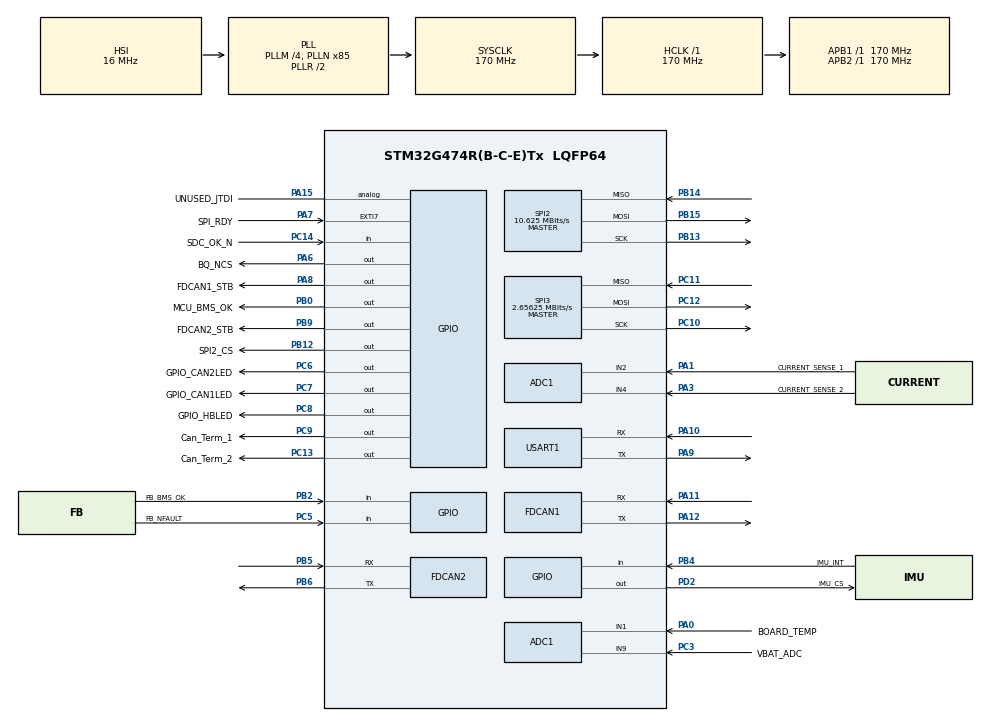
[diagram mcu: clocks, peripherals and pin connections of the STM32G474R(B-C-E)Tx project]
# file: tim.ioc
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ADC1.Channel-0\#ChannelRegularConversion=ADC_CHANNEL_1
ADC1.Channel-1\#ChannelRegularConversion=ADC_CHANNEL_2
ADC1.Channel-2\#ChannelRegularConversion=ADC_CHANNEL_4
ADC1.Channel-3\#ChannelRegularConversion=ADC_CHANNEL_9
ADC1.Channel-4\#ChannelRegularConversion=ADC_CHANNEL_VREFINT
ADC1.ContinuousConvMode=DISABLE
ADC1.DMAContinuousRequests=ENABLE
ADC1.EOCSelection=ADC_EOC_SEQ_CONV
ADC1.ExternalTrigConv=ADC_EXTERNALTRIG_T3_TRGO
ADC1.ExternalTrigConvEdge=ADC_EXTERNALTRIGCONVEDGE_RISING
ADC1.NbrOfConversion=5
ADC1.NbrOfConversionFlag=1
ADC1.OffsetNumber-0\#ChannelRegularConversion=ADC_OFFSET_NONE
ADC1.OffsetNumber-1\#ChannelRegularConversion=ADC_OFFSET_NONE
ADC1.OffsetNumber-2\#ChannelRegularConversion=ADC_OFFSET_NONE
ADC1.OffsetNumber-3\#ChannelRegularConversion=ADC_OFFSET_NONE
ADC1.OffsetNumber-4\#ChannelRegularConversion=ADC_OFFSET_NONE
ADC1.Overrun=ADC_OVR_DATA_OVERWRITTEN
ADC1.Rank-0\#ChannelRegularConversion=1
ADC1.Rank-1\#ChannelRegularConversion=2
ADC1.Rank-2\#ChannelRegularConversion=3
ADC1.Rank-3\#ChannelRegularConversion=4
ADC1.Rank-4\#ChannelRegularConversion=5
ADC1.SamplingTime-0\#ChannelRegularConversion=ADC_SAMPLETIME_640CYCLES_5
ADC1.SamplingTime-1\#ChannelRegularConversion=ADC_SAMPLETIME_640CYCLES_5
ADC1.SamplingTime-2\#ChannelRegularConversion=ADC_SAMPLETIME_640CYCLES_5
ADC1.SamplingTime-3\#ChannelRegularConversion=ADC_SAMPLETIME_640CYCLES_5
ADC1.SamplingTime-4\#ChannelRegularConversion=ADC_SAMPLETIME_640CYCLES_5
ADC1.master=1
Dma.ADC1.2.Direction=DMA_PERIPH_TO_MEMORY
Dma.ADC1.2.EventEnable=DISABLE
Dma.ADC1.2.Instance=DMA1_Channel1
Dma.ADC1.2.MemDataAlignment=DMA_MDATAALIGN_HALFWORD
Dma.ADC1.2.MemInc=DMA_MINC_ENABLE
Dma.ADC1.2.Mode=DMA_CIRCULAR
Dma.ADC1.2.PeriphDataAlignment=DMA_PDATAALIGN_HALFWORD
Dma.ADC1.2.PeriphInc=DMA_PINC_DISABLE
Dma.ADC1.2.Polarity=HAL_DMAMUX_REQ_GEN_RISING
Dma.ADC1.2.Priority=DMA_PRIORITY_HIGH
Dma.ADC1.2.RequestNumber=1
Dma.ADC1.2.SignalID=NONE
Dma.ADC1.2.SyncEnable=DISABLE
Dma.ADC1.2.SyncPolarity=HAL_DMAMUX_SYNC_NO_EVENT
Dma.ADC1.2.SyncRequestNumber=1
Dma.ADC1.2.SyncSignalID=NONE
Dma.Request0=SPI2_RX
Dma.Request1=SPI2_TX
Dma.Request2=ADC1
Dma.Request3=SPI3_RX
Dma.Request4=SPI3_TX
Dma.SPI2_RX.0.Direction=DMA_PERIPH_TO_MEMORY
Dma.SPI2_RX.0.EventEnable=DISABLE
Dma.SPI2_RX.0.Instance=DMA1_Channel3
Dma.SPI2_RX.0.MemDataAlignment=DMA_MDATAALIGN_BYTE
Dma.SPI2_RX.0.MemInc=DMA_MINC_ENABLE
Dma.SPI2_RX.0.Mode=DMA_NORMAL
Dma.SPI2_RX.0.PeriphDataAlignment=DMA_PDATAALIGN_BYTE
Dma.SPI2_RX.0.PeriphInc=DMA_PINC_DISABLE
Dma.SPI2_RX.0.Polarity=HAL_DMAMUX_REQ_GEN_RISING
Dma.SPI2_RX.0.Priority=DMA_PRIORITY_LOW
Dma.SPI2_RX.0.RequestNumber=1
Dma.SPI2_RX.0.SignalID=NONE
Dma.SPI2_RX.0.SyncEnable=DISABLE
Dma.SPI2_RX.0.SyncPolarity=HAL_DMAMUX_SYNC_NO_EVENT
Dma.SPI2_RX.0.SyncRequestNumber=1
Dma.SPI2_RX.0.SyncSignalID=NONE
Dma.SPI2_TX.1.Direction=DMA_MEMORY_TO_PERIPH
Dma.SPI2_TX.1.EventEnable=DISABLE
Dma.SPI2_TX.1.Instance=DMA1_Channel4
Dma.SPI2_TX.1.MemDataAlignment=DMA_MDATAALIGN_BYTE
Dma.SPI2_TX.1.MemInc=DMA_MINC_ENABLE
Dma.SPI2_TX.1.Mode=DMA_NORMAL
Dma.SPI2_TX.1.PeriphDataAlignment=DMA_PDATAALIGN_BYTE
Dma.SPI2_TX.1.PeriphInc=DMA_PINC_DISABLE
Dma.SPI2_TX.1.Polarity=HAL_DMAMUX_REQ_GEN_RISING
Dma.SPI2_TX.1.Priority=DMA_PRIORITY_LOW
Dma.SPI2_TX.1.RequestNumber=1
Dma.SPI2_TX.1.SignalID=NONE
Dma.SPI2_TX.1.SyncEnable=DISABLE
Dma.SPI2_TX.1.SyncPolarity=HAL_DMAMUX_SYNC_NO_EVENT
Dma.SPI2_TX.1.SyncRequestNumber=1
Dma.SPI2_TX.1.SyncSignalID=NONE
Dma.SPI3_RX.3.Direction=DMA_PERIPH_TO_MEMORY
Dma.SPI3_RX.3.EventEnable=DISABLE
Dma.SPI3_RX.3.Instance=DMA1_Channel5
Dma.SPI3_RX.3.MemDataAlignment=DMA_MDATAALIGN_BYTE
Dma.SPI3_RX.3.MemInc=DMA_MINC_ENABLE
Dma.SPI3_RX.3.Mode=DMA_NORMAL
Dma.SPI3_RX.3.PeriphDataAlignment=DMA_PDATAALIGN_BYTE
Dma.SPI3_RX.3.PeriphInc=DMA_PINC_DISABLE
Dma.SPI3_RX.3.Polarity=HAL_DMAMUX_REQ_GEN_RISING
Dma.SPI3_RX.3.Priority=DMA_PRIORITY_HIGH
Dma.SPI3_RX.3.RequestNumber=1
Dma.SPI3_RX.3.SignalID=NONE
Dma.SPI3_RX.3.SyncEnable=DISABLE
Dma.SPI3_RX.3.SyncPolarity=HAL_DMAMUX_SYNC_NO_EVENT
Dma.SPI3_RX.3.SyncRequestNumber=1
Dma.SPI3_RX.3.SyncSignalID=NONE
Dma.SPI3_TX.4.Direction=DMA_MEMORY_TO_PERIPH
Dma.SPI3_TX.4.EventEnable=DISABLE
Dma.SPI3_TX.4.Instance=DMA1_Channel6
Dma.SPI3_TX.4.MemDataAlignment=DMA_MDATAALIGN_BYTE
Dma.SPI3_TX.4.MemInc=DMA_MINC_ENABLE
Dma.SPI3_TX.4.Mode=DMA_NORMAL
Dma.SPI3_TX.4.PeriphDataAlignment=DMA_PDATAALIGN_BYTE
Dma.SPI3_TX.4.PeriphInc=DMA_PINC_DISABLE
Dma.SPI3_TX.4.Polarity=HAL_DMAMUX_REQ_GEN_RISING
Dma.SPI3_TX.4.Priority=DMA_PRIORITY_HIGH
Dma.SPI3_TX.4.RequestNumber=1
Dma.SPI3_TX.4.SignalID=NONE
Dma.SPI3_TX.4.SyncEnable=DISABLE
Dma.SPI3_TX.4.SyncPolarity=HAL_DMAMUX_SYNC_NO_EVENT
Dma.SPI3_TX.4.SyncRequestNumber=1
Dma.SPI3_TX.4.SyncSignalID=NONE
FDCAN1.AutoRetransmission=ENABLE
FDCAN1.CalculateBaudRateNominal=500000
FDCAN1.CalculateTimeBitNominal=2000
FDCAN1.CalculateTimeQuantumNominal=100.0
FDCAN1.ExtFiltersNbr=1
FDCAN1.FrameFormat=FDCAN_FRAME_CLASSIC
FDCAN1.NominalPrescaler=17
FDCAN1.NominalSyncJumpWidth=4
FDCAN1.NominalTimeSeg1=15
FDCAN1.NominalTimeSeg2=4
FDCAN1.TxFifoQueueMode=FDCAN_TX_QUEUE_OPERATION
FDCAN2.AutoRetransmission=ENABLE
FDCAN2.CalculateBaudRateNominal=500000
FDCAN2.CalculateTimeBitNominal=2000
FDCAN2.CalculateTimeQuantumNominal=100.0
FDCAN2.DataPrescaler=5
FDCAN2.DataSyncJumpWidth=3
FDCAN2.DataTimeSeg1=13
FDCAN2.DataTimeSeg2=3
FDCAN2.FrameFormat=FDCAN_FRAME_FD_BRS
FDCAN2.NominalPrescaler=17
FDCAN2.NominalSyncJumpWidth=4
FDCAN2.NominalTimeSeg1=15
FDCAN2.NominalTimeSeg2=4
FREERTOS.Tasks01=initTask,24,128,StartDefaultTask,Default,NULL,Dynamic,NULL,NULL
FREERTOS.configTOTAL_HEAP_SIZE=32768
FREERTOS.configUSE_NEWLIB_REENTRANT=1
Mcu.Family=STM32G4
Mcu.Name=STM32G474R(B-C-E)Tx
Mcu.Package=LQFP64
NVIC.DMA1_Channel1_IRQn=true\:9\:0\:true\:false\:true\:true\:true\:true\:true
NVIC.DMA1_Channel3_IRQn=true\:9\:0\:true\:false\:true\:true\:true\:true\:true
NVIC.DMA1_Channel4_IRQn=true\:9\:0\:true\:false\:true\:true\:true\:true\:true
NVIC.DMA1_Channel5_IRQn=true\:6\:0\:true\:false\:true\:true\:true\:true\:true
NVIC.DMA1_Channel6_IRQn=true\:6\:0\:true\:false\:true\:true\:true\:true\:true
NVIC.EXTI9_5_IRQn=true\:6\:0\:true\:false\:true\:true\:true\:true\:true
NVIC.FDCAN1_IT0_IRQn=true\:5\:0\:false\:false\:true\:true\:true\:true\:true
NVIC.FDCAN1_IT1_IRQn=true\:5\:0\:false\:false\:true\:true\:true\:true\:true
NVIC.FDCAN2_IT0_IRQn=true\:7\:0\:true\:false\:true\:true\:true\:true\:true
NVIC.FDCAN2_IT1_IRQn=true\:7\:0\:true\:false\:true\:true\:true\:true\:true
NVIC.PriorityGroup=NVIC_PRIORITYGROUP_4
NVIC.SPI2_IRQn=true\:9\:0\:true\:false\:true\:true\:true\:true\:true
NVIC.SPI3_IRQn=true\:6\:0\:true\:false\:true\:true\:true\:true\:true
NVIC.TIM6_DAC_IRQn=true\:15\:0\:false\:false\:true\:false\:false\:true\:true
NVIC.TimeBase=TIM6_DAC_IRQn
NVIC.TimeBaseIP=TIM6
NVIC.USART1_IRQn=true\:9\:0\:true\:false\:true\:true\:true\:true\:true
PA0.GPIO_Label=BOARD_TEMP
PA0.Mode=IN1-Single-Ended
PA0.Signal=ADC1_IN1
PA1.GPIO_Label=CURRENT_SENSE_1
PA1.Mode=IN2-Single-Ended
PA1.Signal=ADC1_IN2
PA10.Mode=Asynchronous
PA10.Signal=USART1_RX
PA11.Mode=FDCAN_Activate
PA11.Signal=FDCAN1_RX
PA12.Mode=FDCAN_Activate
PA12.Signal=FDCAN1_TX
PA13.GPIO_Label=SWDIO
PA13.Mode=Trace_Asynchronous_SW
PA13.Signal=SYS_JTMS-SWDIO
PA14.GPIO_Label=SWCLK
PA14.Mode=Trace_Asynchronous_SW
PA14.Signal=SYS_JTCK-SWCLK
PA15.GPIO_Label=UNUSED_JTDI
PA15.Signal=GPIO_Analog
PA3.GPIO_Label=CURRENT_SENSE_2
PA3.Mode=IN4-Single-Ended
PA3.Signal=ADC1_IN4
PA6.GPIO_Label=BQ_NCS
PA6.PinState=GPIO_PIN_SET
PA6.Signal=GPIO_Output
PA7.GPIO_Label=SPI_RDY
PA7.GPIO_ModeDefaultEXTI=GPIO_MODE_IT_RISING
PA7.GPIO_PuPd=GPIO_PULLUP
PA7.Signal=GPXTI7
PA8.GPIO_Label=FDCAN1_STB
PA8.PinState=GPIO_PIN_SET
PA8.Signal=GPIO_Output
PA9.Mode=Asynchronous
PA9.Signal=USART1_TX
PB0.GPIO_Label=MCU_BMS_OK
PB0.GPIO_PuPd=GPIO_NOPULL
PB0.PinState=GPIO_PIN_RESET
PB0.Signal=GPIO_Output
PB12.GPIO_Label=SPI2_CS
PB12.PinState=GPIO_PIN_SET
PB12.Signal=GPIO_Output
PB13.GPIO_Speed=GPIO_SPEED_FREQ_MEDIUM
PB13.Mode=Full_Duplex_Master
PB13.Signal=SPI2_SCK
PB14.Mode=Full_Duplex_Master
PB14.Signal=SPI2_MISO
PB15.GPIO_Speed=GPIO_SPEED_FREQ_MEDIUM
PB15.Mode=Full_Duplex_Master
PB15.Signal=SPI2_MOSI
PB2.GPIO_Label=FB_BMS_OK
PB2.Signal=GPIO_Input
PB3.GPIO_Label=SWO
PB3.Mode=Trace_Asynchronous_SW
PB3.Signal=SYS_JTDO-SWO
PB4.GPIO_Label=IMU_INT
PB4.GPIO_PuPd=GPIO_PULLDOWN
PB4.Signal=GPIO_Input
PB5.Mode=FDCAN_Activate
PB5.Signal=FDCAN2_RX
PB6.Mode=FDCAN_Activate
PB6.Signal=FDCAN2_TX
PB9.GPIO_Label=FDCAN2_STB
PB9.PinState=GPIO_PIN_SET
PB9.Signal=GPIO_Output
PC10.Mode=Full_Duplex_Master
PC10.Signal=SPI3_SCK
PC11.Mode=Full_Duplex_Master
PC11.Signal=SPI3_MISO
PC12.Mode=Full_Duplex_Master
PC12.Signal=SPI3_MOSI
PC13.GPIO_Label=Can_Term_2
PC13.Signal=GPIO_Output
PC14-OSC32_IN.GPIO_Label=SDC_OK_N
PC14-OSC32_IN.Signal=GPIO_Input
PC3.GPIO_Label=VBAT_ADC
PC3.Mode=IN9-Single-Ended
PC3.Signal=ADC1_IN9
PC5.GPIO_Label=FB_NFAULT
PC5.Signal=GPIO_Input
PC6.GPIO_Label=GPIO_CAN2LED
PC6.GPIO_ModeDefaultOutputPP=GPIO_MODE_OUTPUT_PP
PC6.GPIO_PuPd=GPIO_NOPULL
PC6.PinState=GPIO_PIN_SET
PC6.Signal=GPIO_Output
PC7.GPIO_Label=GPIO_CAN1LED
PC7.GPIO_ModeDefaultOutputPP=GPIO_MODE_OUTPUT_PP
PC7.GPIO_PuPd=GPIO_NOPULL
PC7.PinState=GPIO_PIN_SET
PC7.Signal=GPIO_Output
PC8.GPIO_Label=GPIO_HBLED
PC8.GPIO_ModeDefaultOutputPP=GPIO_MODE_OUTPUT_PP
PC8.GPIO_PuPd=GPIO_NOPULL
PC8.PinState=GPIO_PIN_SET
PC8.Signal=GPIO_Output
PC9.GPIO_Label=Can_Term_1
PC9.Signal=GPIO_Output
PD2.GPIO_Label=IMU_CS
PD2.PinState=GPIO_PIN_SET
PD2.Signal=GPIO_Output
PF0-OSC_IN.Mode=HSE-External-Oscillator
PF0-OSC_IN.Signal=RCC_OSC_IN
PF1-OSC_OUT.Mode=HSE-External-Oscillator
PF1-OSC_OUT.Signal=RCC_OSC_OUT
ProjectManager.HeapSize=0x200
ProjectManager.StackSize=0x400
ProjectManager.TargetToolchain=CMake
RCC.ADC12Freq_Value=170000000
RCC.ADC345Freq_Value=170000000
RCC.AHBFreq_Value=170000000
RCC.APB1Freq_Value=170000000
RCC.APB1TimFreq_Value=170000000
RCC.APB2Freq_Value=170000000
RCC.APB2TimFreq_Value=170000000
RCC.CortexFreq_Value=170000000
RCC.EXTERNAL_CLOCK_VALUE=12288000
RCC.HCLKFreq_Value=170000000
RCC.HSE_VALUE=8000000
RCC.HSI48_VALUE=48000000
RCC.HSI_VALUE=16000000
RCC.LSE_VALUE=32768
RCC.PLLM=RCC_PLLM_DIV4
RCC.PLLN=85
RCC.SYSCLKFreq_VALUE=170000000
RCC.SYSCLKSource=RCC_SYSCLKSOURCE_PLLCLK
RCC.USBFreq_Value=170000000
RCC.VCOOutputFreq_Value=340000000
SPI2.BaudRatePrescaler=SPI_BAUDRATEPRESCALER_16
SPI2.CalculateBaudRate=10.625 MBits/s
SPI2.DataSize=SPI_DATASIZE_8BIT
SPI2.Direction=SPI_DIRECTION_2LINES
SPI2.Mode=SPI_MODE_MASTER
SPI2.VirtualType=VM_MASTER
SPI3.BaudRatePrescaler=SPI_BAUDRATEPRESCALER_64
SPI3.CalculateBaudRate=2.65625 MBits/s
SPI3.DataSize=SPI_DATASIZE_8BIT
SPI3.Direction=SPI_DIRECTION_2LINES
SPI3.Mode=SPI_MODE_MASTER
SPI3.VirtualType=VM_MASTER
TIM3.Period=999
TIM3.Prescaler=169
TIM3.TIM_MasterOutputTrigger=TIM_TRGO_UPDATE
USART1.VirtualMode-Asynchronous=VM_ASYNC
VP_ADC1_Vref_Input.Mode=IN-Vrefint
VP_FATFS_VS_Generic.Mode=User_defined
VP_FREERTOS_VS_CMSIS_V2.Mode=CMSIS_V2
VP_SYS_VS_DBSignals.Mode=DisableDeadBatterySignals
VP_SYS_VS_tim6.Mode=TIM6
VP_TIM3_VS_ClockSourceINT.Mode=Internal
board=custom

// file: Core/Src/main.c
/* USER CODE BEGIN Header */
/**
  ******************************************************************************
  * @file           : main.c
  * @brief          : Main program body
  ******************************************************************************
  * @attention
  *
  * Copyright (c) 2026 STMicroelectronics.
  * All rights reserved.
  *
  * This software is licensed under terms that can be found in the LICENSE file
  * in the root directory of this software component.
  * If no LICENSE file comes with this software, it is provided AS-IS.
  *
  ******************************************************************************
  */
/* USER CODE END Header */
#include "main.h"
#include "cmsis_os.h"
#include "app_fatfs.h"

/* USER CODE BEGIN Includes */
#include "tasks.h"
#include "watchdog.h"
#include "crash.h"
#include "reset_info.h"
/* USER CODE END Includes */

ADC_HandleTypeDef hadc1;
DMA_HandleTypeDef hdma_adc1;

FDCAN_HandleTypeDef hfdcan1;
FDCAN_HandleTypeDef hfdcan2;

SPI_HandleTypeDef hspi2;
SPI_HandleTypeDef hspi3;
DMA_HandleTypeDef hdma_spi2_rx;
DMA_HandleTypeDef hdma_spi2_tx;
DMA_HandleTypeDef hdma_spi3_rx;
DMA_HandleTypeDef hdma_spi3_tx;

TIM_HandleTypeDef htim3;

UART_HandleTypeDef huart1;

/* Definitions for initTask */
osThreadId_t initTaskHandle;
const osThreadAttr_t initTask_attributes = {
  .name = "initTask",
  .priority = (osPriority_t) osPriorityNormal,
  .stack_size = 128 * 4
};

void SystemClock_Config(void);
static void MX_GPIO_Init(void);
static void MX_DMA_Init(void);
static void MX_ADC1_Init(void);
static void MX_FDCAN1_Init(void);
static void MX_FDCAN2_Init(void);
static void MX_SPI2_Init(void);
static void MX_SPI3_Init(void);
static void MX_TIM3_Init(void);
static void MX_USART1_UART_Init(void);
void StartDefaultTask(void *argument);

int main(void)
{

  /* USER CODE BEGIN 1 */
  /* Before anything else: read, keep and clear the reset cause, and keep
     the Breadcrumb and Crash record found (reset_info.h, ADR 0011). */
  reset_info_capture();
  /* USER CODE END 1 */

  /* MCU Configuration--------------------------------------------------------*/

  /* Reset of all peripherals, Initializes the Flash interface and the Systick. */
  HAL_Init();

  /* Configure the system clock */
  SystemClock_Config();

  /* Initialize all configured peripherals */
  MX_GPIO_Init();
  MX_DMA_Init();
  MX_ADC1_Init();
  MX_FDCAN1_Init();
  MX_FDCAN2_Init();
  MX_SPI2_Init();
  MX_SPI3_Init();
  MX_TIM3_Init();
  MX_USART1_UART_Init();
  if (MX_FATFS_Init() != APP_OK) {
    Error_Handler();
  }
  /* USER CODE BEGIN 2 */
  /* Start-up Kick 1 of 2, after the peripheral init (watchdog.h). */
  watchdog_kick();
  /* USER CODE END 2 */

  /* Init scheduler */
  osKernelInitialize();

  /* Create the thread(s) */
  /* creation of initTask */
  initTaskHandle = osThreadNew(StartDefaultTask, NULL, &initTask_attributes);

  /* Start scheduler */
  osKernelStart();

  /* We should never get here as control is now taken by the scheduler */

  /* Infinite loop */
  while (1)
  {

  }
}

void SystemClock_Config(void)
{
  RCC_OscInitTypeDef RCC_OscInitStruct = {0};
  RCC_ClkInitTypeDef RCC_ClkInitStruct = {0};

  /** Configure the main internal regulator output voltage
  */
  HAL_PWREx_ControlVoltageScaling(PWR_REGULATOR_VOLTAGE_SCALE1_BOOST);

  /** Initializes the RCC Oscillators according to the specified parameters
  * in the RCC_OscInitTypeDef structure.
  */
  RCC_OscInitStruct.OscillatorType = RCC_OSCILLATORTYPE_HSI;
  RCC_OscInitStruct.HSIState = RCC_HSI_ON;
  RCC_OscInitStruct.HSICalibrationValue = RCC_HSICALIBRATION_DEFAULT;
  RCC_OscInitStruct.PLL.PLLState = RCC_PLL_ON;
  RCC_OscInitStruct.PLL.PLLSource = RCC_PLLSOURCE_HSI;
  RCC_OscInitStruct.PLL.PLLM = RCC_PLLM_DIV4;
  RCC_OscInitStruct.PLL.PLLN = 85;
  RCC_OscInitStruct.PLL.PLLP = RCC_PLLP_DIV2;
  RCC_OscInitStruct.PLL.PLLQ = RCC_PLLQ_DIV2;
  RCC_OscInitStruct.PLL.PLLR = RCC_PLLR_DIV2;
  if (HAL_RCC_OscConfig(&RCC_OscInitStruct) != HAL_OK)
  {
    Error_Handler();
  }

  /** Initializes the CPU, AHB and APB buses clocks
  */
  RCC_ClkInitStruct.ClockType = RCC_CLOCKTYPE_HCLK|RCC_CLOCKTYPE_SYSCLK
                              |RCC_CLOCKTYPE_PCLK1|RCC_CLOCKTYPE_PCLK2;
  RCC_ClkInitStruct.SYSCLKSource = RCC_SYSCLKSOURCE_PLLCLK;
  RCC_ClkInitStruct.AHBCLKDivider = RCC_SYSCLK_DIV1;
  RCC_ClkInitStruct.APB1CLKDivider = RCC_HCLK_DIV1;
  RCC_ClkInitStruct.APB2CLKDivider = RCC_HCLK_DIV1;

  if (HAL_RCC_ClockConfig(&RCC_ClkInitStruct, FLASH_LATENCY_4) != HAL_OK)
  {
    Error_Handler();
  }
}

static void MX_ADC1_Init(void)
{

  ADC_MultiModeTypeDef multimode = {0};
  ADC_ChannelConfTypeDef sConfig = {0};

  /** Common config
  */
  hadc1.Instance = ADC1;
  hadc1.Init.ClockPrescaler = ADC_CLOCK_SYNC_PCLK_DIV4;
  hadc1.Init.Resolution = ADC_RESOLUTION_12B;
  hadc1.Init.DataAlign = ADC_DATAALIGN_RIGHT;
  hadc1.Init.GainCompensation = 0;
  hadc1.Init.ScanConvMode = ADC_SCAN_ENABLE;
  hadc1.Init.EOCSelection = ADC_EOC_SEQ_CONV;
  hadc1.Init.LowPowerAutoWait = DISABLE;
  hadc1.Init.ContinuousConvMode = DISABLE;
  hadc1.Init.NbrOfConversion = 5;
  hadc1.Init.DiscontinuousConvMode = DISABLE;
  hadc1.Init.ExternalTrigConv = ADC_EXTERNALTRIG_T3_TRGO;
  hadc1.Init.ExternalTrigConvEdge = ADC_EXTERNALTRIGCONVEDGE_RISING;
  hadc1.Init.DMAContinuousRequests = ENABLE;
  hadc1.Init.Overrun = ADC_OVR_DATA_OVERWRITTEN;
  hadc1.Init.OversamplingMode = DISABLE;
  if (HAL_ADC_Init(&hadc1) != HAL_OK)
  {
    Error_Handler();
  }

  /** Configure the ADC multi-mode
  */
  multimode.Mode = ADC_MODE_INDEPENDENT;
  if (HAL_ADCEx_MultiModeConfigChannel(&hadc1, &multimode) != HAL_OK)
  {
    Error_Handler();
  }

  /** Configure Regular Channel
  */
  sConfig.Channel = ADC_CHANNEL_1;
  sConfig.Rank = ADC_REGULAR_RANK_1;
  sConfig.SamplingTime = ADC_SAMPLETIME_640CYCLES_5;
  sConfig.SingleDiff = ADC_SINGLE_ENDED;
  sConfig.OffsetNumber = ADC_OFFSET_NONE;
  sConfig.Offset = 0;
  if (HAL_ADC_ConfigChannel(&hadc1, &sConfig) != HAL_OK)
  {
    Error_Handler();
  }

  /** Configure Regular Channel
  */
  sConfig.Channel = ADC_CHANNEL_2;
  sConfig.Rank = ADC_REGULAR_RANK_2;
  if (HAL_ADC_ConfigChannel(&hadc1, &sConfig) != HAL_OK)
  {
    Error_Handler();
  }

  /** Configure Regular Channel
  */
  sConfig.Channel = ADC_CHANNEL_4;
  sConfig.Rank = ADC_REGULAR_RANK_3;
  if (HAL_ADC_ConfigChannel(&hadc1, &sConfig) != HAL_OK)
  {
    Error_Handler();
  }

  /** Configure Regular Channel
  */
  sConfig.Channel = ADC_CHANNEL_9;
  sConfig.Rank = ADC_REGULAR_RANK_4;
  if (HAL_ADC_ConfigChannel(&hadc1, &sConfig) != HAL_OK)
  {
    Error_Handler();
  }

  /** Configure Regular Channel
  */
  sConfig.Channel = ADC_CHANNEL_VREFINT;
  sConfig.Rank = ADC_REGULAR_RANK_5;
  if (HAL_ADC_ConfigChannel(&hadc1, &sConfig) != HAL_OK)
  {
    Error_Handler();
  }

}

static void MX_FDCAN1_Init(void)
{

  hfdcan1.Instance = FDCAN1;
  hfdcan1.Init.ClockDivider = FDCAN_CLOCK_DIV1;
  hfdcan1.Init.FrameFormat = FDCAN_FRAME_CLASSIC;
  hfdcan1.Init.Mode = FDCAN_MODE_NORMAL;
  hfdcan1.Init.AutoRetransmission = ENABLE;
  hfdcan1.Init.TransmitPause = DISABLE;
  hfdcan1.Init.ProtocolException = DISABLE;
  hfdcan1.Init.NominalPrescaler = 17;
  hfdcan1.Init.NominalSyncJumpWidth = 4;
  hfdcan1.Init.NominalTimeSeg1 = 15;
  hfdcan1.Init.NominalTimeSeg2 = 4;
  hfdcan1.Init.DataPrescaler = 1;
  hfdcan1.Init.DataSyncJumpWidth = 1;
  hfdcan1.Init.DataTimeSeg1 = 1;
  hfdcan1.Init.DataTimeSeg2 = 1;
  hfdcan1.Init.StdFiltersNbr = 0;
  hfdcan1.Init.ExtFiltersNbr = 1;
  hfdcan1.Init.TxFifoQueueMode = FDCAN_TX_QUEUE_OPERATION;
  if (HAL_FDCAN_Init(&hfdcan1) != HAL_OK)
  {
    Error_Handler();
  }

}

static void MX_FDCAN2_Init(void)
{

  hfdcan2.Instance = FDCAN2;
  hfdcan2.Init.ClockDivider = FDCAN_CLOCK_DIV1;
  hfdcan2.Init.FrameFormat = FDCAN_FRAME_FD_BRS;
  hfdcan2.Init.Mode = FDCAN_MODE_NORMAL;
  hfdcan2.Init.AutoRetransmission = ENABLE;
  hfdcan2.Init.TransmitPause = DISABLE;
  hfdcan2.Init.ProtocolException = DISABLE;
  hfdcan2.Init.NominalPrescaler = 17;
  hfdcan2.Init.NominalSyncJumpWidth = 4;
  hfdcan2.Init.NominalTimeSeg1 = 15;
  hfdcan2.Init.NominalTimeSeg2 = 4;
  hfdcan2.Init.DataPrescaler = 5;
  hfdcan2.Init.DataSyncJumpWidth = 3;
  hfdcan2.Init.DataTimeSeg1 = 13;
  hfdcan2.Init.DataTimeSeg2 = 3;
  hfdcan2.Init.StdFiltersNbr = 0;
  hfdcan2.Init.ExtFiltersNbr = 0;
  hfdcan2.Init.TxFifoQueueMode = FDCAN_TX_FIFO_OPERATION;
  if (HAL_FDCAN_Init(&hfdcan2) != HAL_OK)
  {
    Error_Handler();
  }

}

static void MX_SPI2_Init(void)
{

  /* SPI2 parameter configuration*/
  hspi2.Instance = SPI2;
  hspi2.Init.Mode = SPI_MODE_MASTER;
  hspi2.Init.Direction = SPI_DIRECTION_2LINES;
  hspi2.Init.DataSize = SPI_DATASIZE_8BIT;
  hspi2.Init.CLKPolarity = SPI_POLARITY_LOW;
  hspi2.Init.CLKPhase = SPI_PHASE_1EDGE;
  hspi2.Init.NSS = SPI_NSS_SOFT;
  hspi2.Init.BaudRatePrescaler = SPI_BAUDRATEPRESCALER_16;
  hspi2.Init.FirstBit = SPI_FIRSTBIT_MSB;
  hspi2.Init.TIMode = SPI_TIMODE_DISABLE;
  hspi2.Init.CRCCalculation = SPI_CRCCALCULATION_DISABLE;
  hspi2.Init.CRCPolynomial = 7;
  hspi2.Init.CRCLength = SPI_CRC_LENGTH_DATASIZE;
  hspi2.Init.NSSPMode = SPI_NSS_PULSE_ENABLE;
  if (HAL_SPI_Init(&hspi2) != HAL_OK)
  {
    Error_Handler();
  }

}

static void MX_SPI3_Init(void)
{

  /* SPI3 parameter configuration*/
  hspi3.Instance = SPI3;
  hspi3.Init.Mode = SPI_MODE_MASTER;
  hspi3.Init.Direction = SPI_DIRECTION_2LINES;
  hspi3.Init.DataSize = SPI_DATASIZE_8BIT;
  hspi3.Init.CLKPolarity = SPI_POLARITY_LOW;
  hspi3.Init.CLKPhase = SPI_PHASE_1EDGE;
  hspi3.Init.NSS = SPI_NSS_SOFT;
  hspi3.Init.BaudRatePrescaler = SPI_BAUDRATEPRESCALER_64;
  hspi3.Init.FirstBit = SPI_FIRSTBIT_MSB;
  hspi3.Init.TIMode = SPI_TIMODE_DISABLE;
  hspi3.Init.CRCCalculation = SPI_CRCCALCULATION_DISABLE;
  hspi3.Init.CRCPolynomial = 7;
  hspi3.Init.CRCLength = SPI_CRC_LENGTH_DATASIZE;
  hspi3.Init.NSSPMode = SPI_NSS_PULSE_ENABLE;
  if (HAL_SPI_Init(&hspi3) != HAL_OK)
  {
    Error_Handler();
  }

}

static void MX_TIM3_Init(void)
{

  TIM_ClockConfigTypeDef sClockSourceConfig = {0};
  TIM_MasterConfigTypeDef sMasterConfig = {0};

  htim3.Instance = TIM3;
  htim3.Init.Prescaler = 169;
  htim3.Init.CounterMode = TIM_COUNTERMODE_UP;
  htim3.Init.Period = 999;
  htim3.Init.ClockDivision = TIM_CLOCKDIVISION_DIV1;
  htim3.Init.AutoReloadPreload = TIM_AUTORELOAD_PRELOAD_DISABLE;
  if (HAL_TIM_Base_Init(&htim3) != HAL_OK)
  {
    Error_Handler();
  }
  sClockSourceConfig.ClockSource = TIM_CLOCKSOURCE_INTERNAL;
  if (HAL_TIM_ConfigClockSource(&htim3, &sClockSourceConfig) != HAL_OK)
  {
    Error_Handler();
  }
  sMasterConfig.MasterOutputTrigger = TIM_TRGO_UPDATE;
  sMasterConfig.MasterSlaveMode = TIM_MASTERSLAVEMODE_DISABLE;
  if (HAL_TIMEx_MasterConfigSynchronization(&htim3, &sMasterConfig) != HAL_OK)
  {
    Error_Handler();
  }

}

static void MX_USART1_UART_Init(void)
{

  huart1.Instance = USART1;
  huart1.Init.BaudRate = 115200;
  huart1.Init.WordLength = UART_WORDLENGTH_8B;
  huart1.Init.StopBits = UART_STOPBITS_1;
  huart1.Init.Parity = UART_PARITY_NONE;
  huart1.Init.Mode = UART_MODE_TX_RX;
  huart1.Init.HwFlowCtl = UART_HWCONTROL_NONE;
  huart1.Init.OverSampling = UART_OVERSAMPLING_16;
  huart1.Init.OneBitSampling = UART_ONE_BIT_SAMPLE_DISABLE;
  huart1.Init.ClockPrescaler = UART_PRESCALER_DIV1;
  huart1.AdvancedInit.AdvFeatureInit = UART_ADVFEATURE_NO_INIT;
  if (HAL_UART_Init(&huart1) != HAL_OK)
  {
    Error_Handler();
  }
  if (HAL_UARTEx_SetTxFifoThreshold(&huart1, UART_TXFIFO_THRESHOLD_1_8) != HAL_OK)
  {
    Error_Handler();
  }
  if (HAL_UARTEx_SetRxFifoThreshold(&huart1, UART_RXFIFO_THRESHOLD_1_8) != HAL_OK)
  {
    Error_Handler();
  }
  if (HAL_UARTEx_DisableFifoMode(&huart1) != HAL_OK)
  {
    Error_Handler();
  }

}

static void MX_DMA_Init(void)
{

  /* DMA controller clock enable */
  __HAL_RCC_DMAMUX1_CLK_ENABLE();
  __HAL_RCC_DMA1_CLK_ENABLE();

  /* DMA interrupt init */
  /* DMA1_Channel1_IRQn interrupt configuration */
  HAL_NVIC_SetPriority(DMA1_Channel1_IRQn, 9, 0);
  HAL_NVIC_EnableIRQ(DMA1_Channel1_IRQn);
  /* DMA1_Channel3_IRQn interrupt configuration */
  HAL_NVIC_SetPriority(DMA1_Channel3_IRQn, 9, 0);
  HAL_NVIC_EnableIRQ(DMA1_Channel3_IRQn);
  /* DMA1_Channel4_IRQn interrupt configuration */
  HAL_NVIC_SetPriority(DMA1_Channel4_IRQn, 9, 0);
  HAL_NVIC_EnableIRQ(DMA1_Channel4_IRQn);
  /* DMA1_Channel5_IRQn interrupt configuration */
  HAL_NVIC_SetPriority(DMA1_Channel5_IRQn, 6, 0);
  HAL_NVIC_EnableIRQ(DMA1_Channel5_IRQn);
  /* DMA1_Channel6_IRQn interrupt configuration */
  HAL_NVIC_SetPriority(DMA1_Channel6_IRQn, 6, 0);
  HAL_NVIC_EnableIRQ(DMA1_Channel6_IRQn);

}

static void MX_GPIO_Init(void)
{
  GPIO_InitTypeDef GPIO_InitStruct = {0};

  /* GPIO Ports Clock Enable */
  __HAL_RCC_GPIOC_CLK_ENABLE();
  __HAL_RCC_GPIOF_CLK_ENABLE();
  __HAL_RCC_GPIOA_CLK_ENABLE();
  __HAL_RCC_GPIOB_CLK_ENABLE();
  __HAL_RCC_GPIOD_CLK_ENABLE();

  /*Configure GPIO pin Output Level */
  HAL_GPIO_WritePin(GPIOC, Can_Term_2_Pin|Can_Term_1_Pin, GPIO_PIN_RESET);

  /*Configure GPIO pin Output Level */
  HAL_GPIO_WritePin(GPIOA, BQ_NCS_Pin|FDCAN1_STB_Pin, GPIO_PIN_SET);

  /*Configure GPIO pin Output Level */
  HAL_GPIO_WritePin(MCU_BMS_OK_GPIO_Port, MCU_BMS_OK_Pin, GPIO_PIN_RESET);

  /*Configure GPIO pin Output Level */
  HAL_GPIO_WritePin(GPIOB, SPI2_CS_Pin|FDCAN2_STB_Pin, GPIO_PIN_SET);

  /*Configure GPIO pin Output Level */
  HAL_GPIO_WritePin(GPIOC, GPIO_CAN2LED_Pin|GPIO_CAN1LED_Pin|GPIO_HBLED_Pin, GPIO_PIN_SET);

  /*Configure GPIO pin Output Level */
  HAL_GPIO_WritePin(IMU_CS_GPIO_Port, IMU_CS_Pin, GPIO_PIN_SET);

  /*Configure GPIO pins : Can_Term_2_Pin GPIO_CAN2LED_Pin GPIO_CAN1LED_Pin GPIO_HBLED_Pin
                           Can_Term_1_Pin */
  GPIO_InitStruct.Pin = Can_Term_2_Pin|GPIO_CAN2LED_Pin|GPIO_CAN1LED_Pin|GPIO_HBLED_Pin
                          |Can_Term_1_Pin;
  GPIO_InitStruct.Mode = GPIO_MODE_OUTPUT_PP;
  GPIO_InitStruct.Pull = GPIO_NOPULL;
  GPIO_InitStruct.Speed = GPIO_SPEED_FREQ_LOW;
  HAL_GPIO_Init(GPIOC, &GPIO_InitStruct);

  /*Configure GPIO pins : SDC_OK_N_Pin FB_NFAULT_Pin */
  GPIO_InitStruct.Pin = SDC_OK_N_Pin|FB_NFAULT_Pin;
  GPIO_InitStruct.Mode = GPIO_MODE_INPUT;
  GPIO_InitStruct.Pull = GPIO_NOPULL;
  HAL_GPIO_Init(GPIOC, &GPIO_InitStruct);

  /*Configure GPIO pins : BQ_NCS_Pin FDCAN1_STB_Pin */
  GPIO_InitStruct.Pin = BQ_NCS_Pin|FDCAN1_STB_Pin;
  GPIO_InitStruct.Mode = GPIO_MODE_OUTPUT_PP;
  GPIO_InitStruct.Pull = GPIO_NOPULL;
  GPIO_InitStruct.Speed = GPIO_SPEED_FREQ_LOW;
  HAL_GPIO_Init(GPIOA, &GPIO_InitStruct);

  /*Configure GPIO pin : SPI_RDY_Pin */
  GPIO_InitStruct.Pin = SPI_RDY_Pin;
  GPIO_InitStruct.Mode = GPIO_MODE_IT_RISING;
  GPIO_InitStruct.Pull = GPIO_PULLUP;
  HAL_GPIO_Init(SPI_RDY_GPIO_Port, &GPIO_InitStruct);

  /*Configure GPIO pins : MCU_BMS_OK_Pin SPI2_CS_Pin FDCAN2_STB_Pin */
  GPIO_InitStruct.Pin = MCU_BMS_OK_Pin|SPI2_CS_Pin|FDCAN2_STB_Pin;
  GPIO_InitStruct.Mode = GPIO_MODE_OUTPUT_PP;
  GPIO_InitStruct.Pull = GPIO_NOPULL;
  GPIO_InitStruct.Speed = GPIO_SPEED_FREQ_LOW;
  HAL_GPIO_Init(GPIOB, &GPIO_InitStruct);

  /*Configure GPIO pin : FB_BMS_OK_Pin */
  GPIO_InitStruct.Pin = FB_BMS_OK_Pin;
  GPIO_InitStruct.Mode = GPIO_MODE_INPUT;
  GPIO_InitStruct.Pull = GPIO_NOPULL;
  HAL_GPIO_Init(FB_BMS_OK_GPIO_Port, &GPIO_InitStruct);

  /*Configure GPIO pin : UNUSED_JTDI_Pin */
  GPIO_InitStruct.Pin = UNUSED_JTDI_Pin;
  GPIO_InitStruct.Mode = GPIO_MODE_ANALOG;
  GPIO_InitStruct.Pull = GPIO_NOPULL;
  HAL_GPIO_Init(UNUSED_JTDI_GPIO_Port, &GPIO_InitStruct);

  /*Configure GPIO pin : IMU_CS_Pin */
  GPIO_InitStruct.Pin = IMU_CS_Pin;
  GPIO_InitStruct.Mode = GPIO_MODE_OUTPUT_PP;
  GPIO_InitStruct.Pull = GPIO_NOPULL;
  GPIO_InitStruct.Speed = GPIO_SPEED_FREQ_LOW;
  HAL_GPIO_Init(IMU_CS_GPIO_Port, &GPIO_InitStruct);

  /*Configure GPIO pin : IMU_INT_Pin */
  GPIO_InitStruct.Pin = IMU_INT_Pin;
  GPIO_InitStruct.Mode = GPIO_MODE_INPUT;
  GPIO_InitStruct.Pull = GPIO_PULLDOWN;
  HAL_GPIO_Init(IMU_INT_GPIO_Port, &GPIO_InitStruct);

  /* EXTI interrupt init*/
  HAL_NVIC_SetPriority(EXTI9_5_IRQn, 6, 0);
  HAL_NVIC_EnableIRQ(EXTI9_5_IRQn);

  /* USER CODE BEGIN MX_GPIO_Init_2 */
  /* Straight after GPIO init, with every pin at its safe level (ADR 0013,
     watchdog.h). */
  watchdog_start();
  /* USER CODE END MX_GPIO_Init_2 */
}

void StartDefaultTask(void *argument)
{
  /* USER CODE BEGIN 5 */
  tasks_init();
  osThreadTerminate(osThreadGetId());
  /* USER CODE END 5 */
}

void HAL_TIM_PeriodElapsedCallback(TIM_HandleTypeDef *htim)
{
  if (htim->Instance == TIM6)
  {
    HAL_IncTick();
  }
}

void Error_Handler(void)
{
  /* USER CODE BEGIN Error_Handler_Debug */
  /* The crash routine (crash.h), recording who called this. */
  crash_now(CRASH_ERROR_HANDLER, (uint32_t)(uintptr_t)__builtin_return_address(0));
  /* USER CODE END Error_Handler_Debug */
}
#ifdef USE_FULL_ASSERT
/**
  * @brief  Reports the name of the source file and the source line number
  *         where the assert_param error has occurred.
  * @param  file: pointer to the source file name
  * @param  line: assert_param error line source number
  * @retval None
  */
void assert_failed(uint8_t *file, uint32_t line)
{
  /* USER CODE BEGIN 6 */
  /* The crash routine (crash.h), as for configASSERT. */
  (void)file;
  (void)line;
  crash_now(CRASH_ASSERT, (uint32_t)(uintptr_t)__builtin_return_address(0));
  /* USER CODE END 6 */
}
#endif /* USE_FULL_ASSERT */
